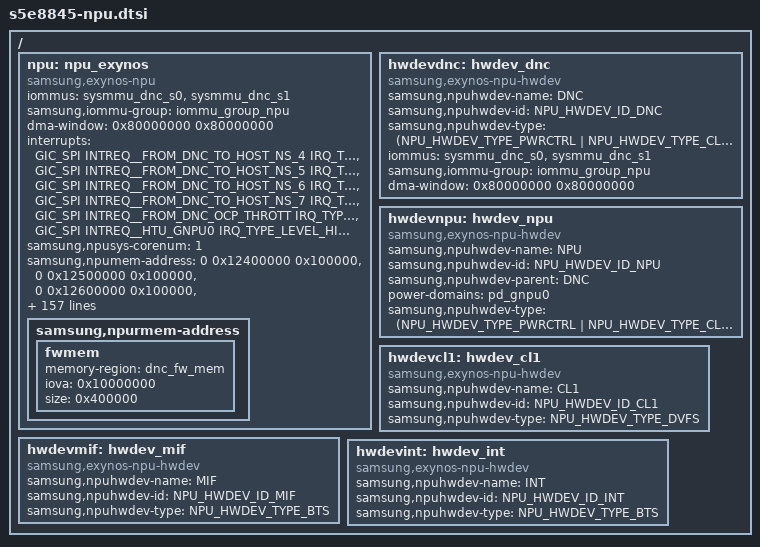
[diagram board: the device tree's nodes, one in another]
/*
 * SAMSUNG EXYNOS9945 NPU device tree source
 *
 * Copyright (c) 2023 Samsung Electronics Co., Ltd.
 *		http://www.samsung.com
 *
 * SAMSUNG EXYNOS9945 NPU device nodes are listed in this file.
 * EXYNOS based board files can include this file and provide
 * values for board specfic bindings.
 *
 * This program is free software; you can redistribute it and/or modify
 * it under the terms of the GNU General Public License version 2 as
 * published by the Free Software Foundation.
 */
#include <dt-bindings/clock/s5e8845.h>
#include <dt-bindings/soc/samsung/s5e8845-npu.h>

/ {
	npu: npu_exynos {
		compatible = "samsung,exynos-npu";
		iommus = <&sysmmu_dnc_s0>, <&sysmmu_dnc_s1>;
		samsung,iommu-group = <&iommu_group_npu>;
		#dma-address-cells = <1>;
		#dma-size-cells = <1>;
		dma-window = <0x80000000 0x80000000>;

		interrupts =
			<GIC_SPI INTREQ__FROM_DNC_TO_HOST_NS_4 IRQ_TYPE_LEVEL_HIGH>,
			<GIC_SPI INTREQ__FROM_DNC_TO_HOST_NS_5 IRQ_TYPE_LEVEL_HIGH>,
			<GIC_SPI INTREQ__FROM_DNC_TO_HOST_NS_6 IRQ_TYPE_LEVEL_HIGH>,
			<GIC_SPI INTREQ__FROM_DNC_TO_HOST_NS_7 IRQ_TYPE_LEVEL_HIGH>,
			<GIC_SPI INTREQ__FROM_DNC_OCP_THROTT IRQ_TYPE_LEVEL_HIGH>,
			<GIC_SPI INTREQ__HTU_GNPU0 IRQ_TYPE_LEVEL_HIGH>;

		samsung,npusys-corenum = <1>;
		/* refer to npu-system.h for memory names
		 * you can add init settings for each memory area
		 */
		samsung,npumem-address = /* 0 start      size */
			<0 0x12400000 0x100000>,
			<0 0x12500000 0x100000>,
			<0 0x12600000 0x100000>,

			<0 0x12200000 0x200000>,
			<0 0x12000000 0x200000>,
			<0 0x12100000 0x100000>,

			//<0 0x22B00000 0x100000>,

			<0 0x12420000 0x1000>,
			<0 0x1242084C 0x100>,
			<0 0x12420824 0x100>,
			<0 0x12420838 0x100>,
			<0 0x123D0000 0x1000>,		//htu_dnc

			<0 0x10D00000 0x200000>,
			<0 0x12F00000 0x800000>,
			<0 0x10C00000 0x1000>,
			<0 0x10C08000 0xF8000>,
			<0 0x21000000 0x40000000>,
			<0 0x21000000 0x20000000>,
			<0 0x41000000 0x20000000>,
			<0 0x0 0x2800>;
		samsung,npumem-names =
				"sfrdnc",	"SFR",
				"sfrsdma",	"SFR",
				"sfrgnpu0",	"SFR",

				"sfrblkdnc",	"SFR",
				"sfrblksdma",	"SFR",
				"sfrblkgnpu0",	"SFR",

				//"sfrfreq",	"SFR",

				"sfrmbox",	"SFR",
				"sfrmbox0",	"SFR",
				"sfrmbox1",	"SFR",
				"sfrmbox2",	"SFR",
				"htudnc",	"SFR",

				"fwmbox",	"fwmbox",
				"fwunittest",	"fwunittest",
				"dhcp",		"dhcp",
				"fwlog",	"fwlog",
				"CHUNK_IMB",	"IMB",
				"CHUNK_IMBl",	"IMB",
				"CHUNK_IMBh",   "IMB",
				"CMDQ_TABLE",	"";

		/* examples of memory area init
		 *	offset,	val,	mask,
		 * samsung,npumem-baaw =
		 *	<0x00, 0x017B00, 0xFFFFFF>,
		 *	<0x00, 0x017B40, 0xFFFFFF>,
		 *	...;
		 */

		/* examples of reg cmd
		 *	sfr : name of memory area
		 *	data :
		 *	<rw	offset	val	mask	mdelay>,
		 */

		samsung,npucmd-cpuon-sfr =
			/* DNC boot up */
			"sfrdnc",
			"sfrdnc",
			"sfrdnc",
			"sfrdnc",
			"sfrdnc",
			"sfrdnc",
			"sfrdnc";
		/*	cmd	offset	value	mask		delay */
		samsung,npucmd-cpuon-data =
		/* to power on, DNC_CPU_ALIVE_CTRL.CPU_ALIVE_CTRL should be 0 */
			<3	0xE0054	0x00000000	0xFFFFFFFF	0>,
			<1	0xE011C	0x00000000	0xFFFFFFFF	0>,
			<1	0xE0000	0x00000001	0xFFFFFFFF	0>,
			<3	0xE0004	0x00000001	0xFFFFFFFF	0>,
			<1	0xE0008	0x10000000	0xFFFFFFFF	0>,
			<3	0xE000C	0x10000000	0xFFFFFFFF	0>,
			<3	0xE0040	0x00000003	0xFFFFFFFF	0>;

		samsung,npucmd-cpuon64-sfr =
			/* DNC boot up */
			"sfrdnc",
			"sfrdnc",
			"sfrdnc",
			"sfrdnc",
			"sfrdnc",
			"sfrdnc",
			"sfrdnc";
		/*	cmd	offset	value	mask		delay */
		samsung,npucmd-cpuon64-data =
		/* to power on, DNC_CPU_ALIVE_CTRL.CPU_ALIVE_CTRL should be 0 */
			<3	0xE0054	0x00000001	0xFFFFFFFF	0>,
			<1	0xE011C	0x00000000	0xFFFFFFFF	0>,
			<1	0xE0000	0x00000001	0xFFFFFFFF	0>,
			<3	0xE0004	0x00000001	0xFFFFFFFF	0>,
			<1	0xE0008	0x10000000	0xFFFFFFFF	0>,
			<3	0xE000C	0x10000000	0xFFFFFFFF	0>,
			<3	0xE0040	0x00000003	0xFFFFFFFF	0>;

		samsung,npucmd-cpuoff-sfr =
			"sfrdnc";
		samsung,npucmd-cpuoff-data =
		/* to power off NPU cores, HWACG should be enable */
			<3	0xE0040	0x00000000	0xFFFFFFFF	0>;

		samsung,npucmd-cpupc-sfr =
			"sfrdnc",
			"sfrdnc";
		samsung,npucmd-cpupc-data =
			<0	0xE00CC	0x00	0xFFFFFFFF	0>,
			<0	0xE00D0	0x00	0xFFFFFFFF	0>;

		samsung,npucmd-afmdncen-sfr =
			"htudnc",
			"htudnc",
			"htudnc",
			"htudnc",
			"htudnc",
			"htudnc",
			"htudnc",
			"htudnc";
		samsung,npucmd-afmdncen-data =
			<1	0x200	0x00000020	0x00000020	0>,
			<1	0x06C	0x08A00018	0x08E000FC	0>,
			<1	0x080	0x02000001	0xFFF0FFF3	0>,
			<1	0x020	0x00003000	0x00003800	0>,
			<1	0x048	0x3FF0007F	0x3FF000FF	0>,
			<1	0x200	0x80000000	0x80000000	0>,
			<1	0x118	0x80000000	0xFFFFFFFF	0>,
			<1	0x000	0x00000001	0x00000001	0>;

		samsung,npucmd-afmdncdis-sfr =
			"htudnc",
			"htudnc",
			"htudnc",
			"htudnc",
			"htudnc",
			"htudnc",
			"htudnc",
			"htudnc";
		samsung,npucmd-afmdncdis-data =
			<1	0x200	0x00	0x00000020	0>,
			<1	0x06C	0x00	0x08E000FC	0>,
			<1	0x080	0x00	0xFFF0FFF3	0>,
			<1	0x020	0x00	0x00003800	0>,
			<1	0x048	0x00	0x3FF000FF	0>,
			<1	0x200	0x00	0x80000000	0>,
			<1	0x118	0x00	0xFFFFFFFF	0>,
			<1	0x000	0x00	0x00000001	0>;

		samsung,npucmd-chkdncitr-sfr =
			"htudnc";
		samsung,npucmd-chkdncitr-data =
			<0	0x06C	0x08000000	0x08000000	0>;

		samsung,npucmd-clrdncitr-sfr =
			"htudnc";
		samsung,npucmd-clrdncitr-data =
			<1	0x06C	0x08000000	0x08000000	0>;

		samsung,npucmd-endncitr-sfr =
			"htudnc";
		samsung,npucmd-endncitr-data =
			<1	0x080	0x00000003	0x00000003	0>;

		samsung,npucmd-disdncitr-sfr =
			"htudnc";
		samsung,npucmd-disdncitr-data =
			<1	0x080	0x00	0x00000003	0>;

		samsung,npucmd-clrdnctdc-sfr =
			"htudnc";
		samsung,npucmd-clrdnctdc-data =
			<1	0x080	0x00	0x0000FFF0	0>;

		samsung,npucmd-chkdnctdc-sfr =
			"htudnc";
		samsung,npucmd-chkdnctdc-data =
			<0	0x080	0x00	0x0000FFF0	0>;

		samsung,npucmd-clrdncdiv-sfr =
			"sfrblkdnc",
			"sfrblksdma";
		samsung,npucmd-clrdncdiv-data =
			<1	0x830	0x00	0x00000010	0>,
			<1	0x830	0x00	0x00000010	0>;

		samsung,npucmd-printafmst-sfr =
			"sfrblkdnc",
			"sfrblkdnc",
			"sfrblkdnc",
			"sfrblksdma",
			"sfrblksdma",
			"sfrblksdma",
			"sfrblkgnpu0",
			"sfrblkgnpu0",
			"sfrblkgnpu0";

		samsung,npucmd-printafmst-data =
			<2	0x830	0x00	0xFFFFFFFF	0>,
			<2	0x834	0x00	0xFFFFFFFF	0>,
			<2	0x838	0x00	0xFFFFFFFF	0>,
			<2	0x830	0x00	0xFFFFFFFF	0>,
			<2	0x834	0x00	0xFFFFFFFF	0>,
			<2	0x838	0x00	0xFFFFFFFF	0>,
			<2	0x830	0x00	0xFFFFFFFF	0>,
			<2	0x838	0x00	0xFFFFFFFF	0>,
			<2	0x83C	0x00	0xFFFFFFFF	0>;

		samsung,npucmd-fwpwm-sfr =
			"sfrdnc";
		/*	cmd	offset	value	mask		delay */
		samsung,npucmd-fwpwm-data =
			<0	0x5002c	0x00	0xFFFFFFFF	0>;

		samsung,imgloader-s2mpu-support = "true";
		samsung,npusched-tpf-others = <1500>;	/* time in device driver, us */
		samsung,npusched-afmlimit = <800000>;
		samsung,npusched-min-active-cores = <1>; /* FW needs atleast one core to be active */

		samsung,npusched-dvfs =
			/* devfreq      init    delay   up      delay   down    delay
			* hispeed_idle_delay hispeed_delay hispeed_freq lowspeed_idle_delay    : exynos-interactive
			* normal       npu     cpu                             : mode minlock freq
			*/
			<&devfreq_2     1066000	30      120     75      85      75
				30      0       100     100
				1066000	1066000	0	0	1066000	1066000>,
			<&devfreq_3     800000	30      120     75      85      30
				30      0       100     100
				800000	800000	0	0	800000	800000>,
			<&devfreq_1	0	0	0	0	0	0
				0	0	0	0
				0	0	0	0	0	0>,
			<&devfreq_0	0	0	0	0	0	0
				0	0	0	0
				0	0	0	0	0	0>
		;

		samsung,npusched-names =
			"NPU0",  "exynos-interactive",
			"DNC",  "exynos-interactive",
			"INT",	"",
			"MIF",	""
		;

		samsung,npudvfs-open-dvfs =
			"DNC",
			"NPU0";
		samsung,npudvfs-open-clock =
			<0	267000>,
			<0	333000>;

		samsung,npudvfs-close-dvfs =
			"DNC",
			"NPU0";

		samsung,npudvfs-close-clock =
			<0	0>,
			<0	0>;

		samsung,npudvfs-table-num =
			/* table_index	type_num */
			<3 4>;

		samsung,npudvfs-table =
			/* core      dnc       mif      int */
			<1066000 800000 3172000 666000>,
			<666000 533000 1539000 333000>,
			<333000 267000 676000 80000>;

		samsung,npugovernor-num =
			/* npu mif int */
			<6 13 13>;

		samsung,npugovernor-npufreq =
			/* dnc   core */
			<267000 333000>,
			<333000 333000>,
			<444000 400000>,
			<533000 666000>,
			<666000 800000>,
			<800000 1066000>;

		samsung,npugovernor-miffreq =
			<421000>,
			<546000>,
			<676000>,
			<845000>,
			<1014000>,
			<1352000>,
			<1539000>,
			<1794000>,
			<2093000>,
			<2288000>,
			<2535000>,
			<2730000>,
			<3172000>;

		samsung,npugovernor-intfreq =
			<80000>,
			<80000>,
			<134000>,
			<134000>,
			<267000>,
			<267000>,
			<333000>,
			<333000>,
			<444000>,
			<444000>,
			<533000>,
			<533000>,
			<666000>;

		samsung,npudtm-param =
			/* target_thermal p_gain i_gain inv_gain period limit_thermal limit_frequncy */
			<93000 300 1 300 1 85000 800000>;

		samsung,npuinter-isr-cpu-affinity = "4-6";

		samsung,npuproto-task-priority = <1>;	/* SCHED_FIFO, 1 */
		samsung,npuproto-task-cpu-affinity = "4-6";

		samsung,npuafm-gnpu0-offset = <0x68>;
		samsung,npuafm-gnpu0-level = <0x00>;

		status = "ok";

		vertex_name = "npu";

		configs =
			<16>,		/* NPU_MAX_BUFFER */
			<3>,		/* NPU_MAX_PLANE */
			<32>,		/* NPU_MAX_GRAPH */
			<16>,		/* NPU_MAX_FRAME */
			<10>,		/* NPU_MINOR */
			<1024>,		/* NW_Q_SIZE */
			<1024>,		/* FRAME_Q_SIZE */
			<4194304>,	/* NPU_FW_LOG_KEEP_SIZE */
			<0>,		/* NPU_MAILBOX_DEFAULT_TID */
			<20>,		/* TCNTO0_OFF */
			<4096>,		/* NPU_MAILBOX_HDR_SECTION_LEN */
			<32768>,	/* NPU_MAILBOX_SIZE */
			<0x80000>,	/* NPU_MAILBOX_BASE */
			<300>,		/* POWER_DOWN_DELAY_ON_EMERGENCY */
			<12000>,	/* STREAMOFF_DELAY_ON_EMERGENCY */
			<0>,		/* NPU_FW_BASE_ADDR */
			<0>,		/* NPU_CM7_RELEASE_HACK */
			<0x50E00000>,	/* NPU_SHARED_MEM_PAYLOAD */
			<0x17EB0000>,	/* NPU_C2AGENT_0 */
			<0x17EC0000>,	/* NPU_C2AGENT_1 */
			<0x15010000>,	/* NPU_VOTF */
			<0x10000>,	/* NPU_VOTF_SIZE */
			<0>,		/* PBHA_HINT_00 */
			<1>,		/* PBHA_HINT_01 */
			<2>,		/* PBHA_HINT_10 */
			<3>,		/* PBHA_HINT_11 */
			<0x80000000>,   /* TRANSACTIONS_PER_CORE */
			<0x02000000>,   /* CMDQ_COMPLEXITY_PER_CORE */
			<1000000>,      /* LASTQ_TIME_THRESHOLD */
			<399>,		/* ALPHA */
			<24684>,	/* BETA */
			<3000>,		/* Time for clk setting */
			<0x40000000>	/* NPU IMB THRESHOLD SIZE */
			;

		samsung,npurmem-address {
			fwmem {
				memory-region = <&dnc_fw_mem>;
				iova = <0x10000000>;
				size =   <0x400000>;
			};
		};
	};

	hwdevdnc: hwdev_dnc {
		compatible = "samsung,exynos-npu-hwdev";

		samsung,npuhwdev-name = "DNC";
		samsung,npuhwdev-id = <NPU_HWDEV_ID_DNC>;

//		clocks = <&clock UMUX_CLKCMU_DNC_NOC>;
//		clock-names = "dnc_noc";

		/* iommu already has parent as <&pd_npus> */
//		power-domains = <&pd_sdma>;

		samsung,npuhwdev-type =
			<(NPU_HWDEV_TYPE_PWRCTRL | NPU_HWDEV_TYPE_CLKCTRL)>;

		iommus = <&sysmmu_dnc_s0>, <&sysmmu_dnc_s1>;
		samsung,iommu-group = <&iommu_group_npu>;
		#dma-address-cells = <1>;
		#dma-size-cells = <1>;
		dma-window = <0x80000000 0x80000000>;
		status = "ok";
	};

	hwdevnpu: hwdev_npu {
		compatible = "samsung,exynos-npu-hwdev";

		samsung,npuhwdev-name = "NPU";
		samsung,npuhwdev-id = <NPU_HWDEV_ID_NPU>;
		samsung,npuhwdev-parent = "DNC";
/*
		clocks =
			<&clock UMUX_CLKCMU_NPU0_BUS_USER>;
		clock-names =
			"npu00_bus";
*/

		power-domains = <&pd_gnpu0>;

		samsung,npuhwdev-type =
			<(NPU_HWDEV_TYPE_PWRCTRL | NPU_HWDEV_TYPE_CLKCTRL | NPU_HWDEV_TYPE_DVFS)>;

		status = "ok";
	};

	hwdevcl1: hwdev_cl1 {
		compatible = "samsung,exynos-npu-hwdev";

		samsung,npuhwdev-name = "CL1";
		samsung,npuhwdev-id = <NPU_HWDEV_ID_CL1>;

		samsung,npuhwdev-type =
			<NPU_HWDEV_TYPE_DVFS>;

		status = "ok";
	};

	hwdevmif: hwdev_mif {
		compatible = "samsung,exynos-npu-hwdev";

		samsung,npuhwdev-name = "MIF";
		samsung,npuhwdev-id = <NPU_HWDEV_ID_MIF>;

		samsung,npuhwdev-type =
			<NPU_HWDEV_TYPE_BTS>;

		status = "ok";
	};

	hwdevint: hwdev_int {
		compatible = "samsung,exynos-npu-hwdev";

		samsung,npuhwdev-name = "INT";
		samsung,npuhwdev-id = <NPU_HWDEV_ID_INT>;

		samsung,npuhwdev-type =
			<NPU_HWDEV_TYPE_BTS>;

		status = "ok";
	};
};
